# STM32F207 register map
File version: 1.2
CPU: CM3 r1p1, little endian, no MPU, no FPU, 4 interrupt priority bits
Registers are 32-bit, read-write, reset 0x0 unless marked. A register's access mark holds for its fields unless they carry their own. Offsets are from the block's base; [hi:lo] are bit positions; {n}, {i} and the like mark numbered series; 'fields as' and 'values as' point back to an identical list.

## Ethernet_PTP — Ethernet: Precision time protocol
Base 0x40028700
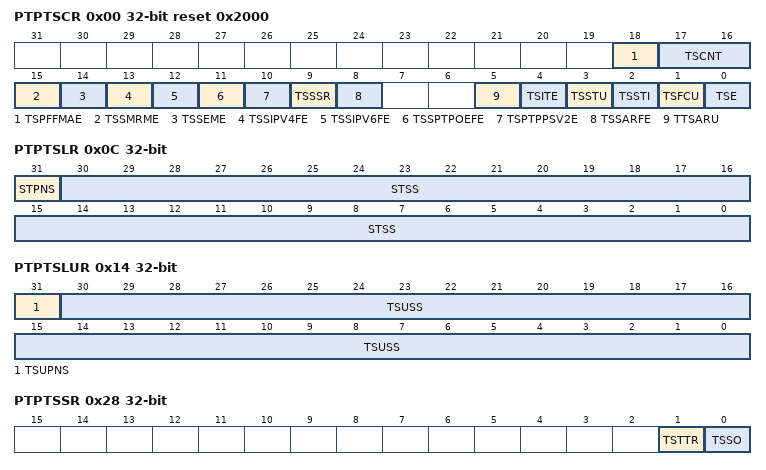
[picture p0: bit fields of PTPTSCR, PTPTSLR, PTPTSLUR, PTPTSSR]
0x00 PTPTSCR reset 0x2000 — Ethernet PTP time stamp control register
  [18] TSPFFMAE — Time stamp PTP frame filtering MAC address enable
  [17:16] TSCNT — Time stamp clock node type
  [15] TSSMRME — Time stamp snapshot for message relevant to master enable
  [14] TSSEME — Time stamp snapshot for event message enable
  [13] TSSIPV4FE — Time stamp snapshot for IPv4 frames enable
  [12] TSSIPV6FE — Time stamp snapshot for IPv6 frames enable
  [11] TSSPTPOEFE — Time stamp snapshot for PTP over ethernet frames enable
  [10] TSPTPPSV2E — Time stamp PTP packet snooping for version2 format enable
  [9] TSSSR — Time stamp subsecond rollover: digital or binary rollover control
  [8] TSSARFE — Time stamp snapshot for all received frames enable
  [5] TTSARU — Time stamp addend register update
  [4] TSITE — Time stamp interrupt trigger enable
  [3] TSSTU — Time stamp system time update
  [2] TSSTI — Time stamp system time initialize
  [1] TSFCU — Time stamp fine or coarse update
  [0] TSE — Time stamp enable
0x04 PTPSSIR — Ethernet PTP subsecond increment register
  [7:0] STSSI — System time subsecond increment
0x08 PTPTSHR ro — Ethernet PTP time stamp high register
  [31:0] STS — System time second
0x0C PTPTSLR ro — Ethernet PTP time stamp low register
  [31] STPNS — System time positive or negative sign
  [30:0] STSS — System time subseconds
0x10 PTPTSHUR — Ethernet PTP time stamp high update register
  [31:0] TSUS — Time stamp update second
0x14 PTPTSLUR — Ethernet PTP time stamp low update register
  [31] TSUPNS — Time stamp update positive or negative sign
  [30:0] TSUSS — Time stamp update subseconds
0x18 PTPTSAR — Ethernet PTP time stamp addend register
  [31:0] TSA — Time stamp addend
0x1C PTPTTHR — Ethernet PTP target time high register
  [31:0] TTSH — Target time stamp high
0x20 PTPTTLR — Ethernet PTP target time low register
  [31:0] TTSL — Target time stamp low
0x28 PTPTSSR ro — Ethernet PTP time stamp status register
  [1] TSTTR — Time stamp target time reached
  [0] TSSO — Time stamp second overflow
0x2C PTPPPSCR ro — Ethernet PTP PPS control register
  [3:0] PPSFREQ — PPS frequency selection

## FLASH
Base 0x40023C00
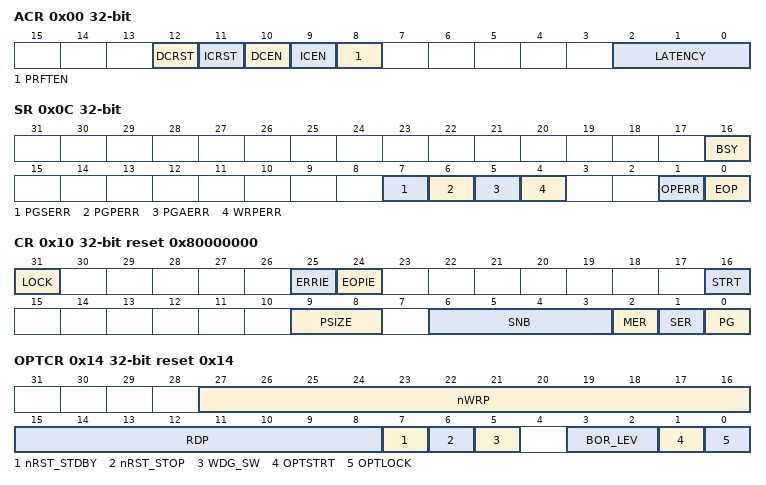
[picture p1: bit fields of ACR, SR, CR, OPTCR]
0x00 ACR access per field — Flash access control register
  [12] DCRST rw — Data cache reset
  [11] ICRST wo — Instruction cache reset
  [10] DCEN rw — Data cache enable
  [9] ICEN rw — Instruction cache enable
  [8] PRFTEN rw — Prefetch enable
  [2:0] LATENCY rw
0x04 KEYR wo — Flash key register
  [31:0] KEY — FPEC key
0x08 OPTKEYR wo — Flash option key register
  [31:0] OPTKEY — Option byte key
0x0C SR access per field — Status register
  [16] BSY ro — Busy
  [7] PGSERR rw — Programming sequence error
  [6] PGPERR rw — Programming parallelism error
  [5] PGAERR rw — Programming alignment error
  [4] WRPERR rw — Write protection error
  [1] OPERR rw — Operation error
  [0] EOP rw — End of operation
0x10 CR reset 0x80000000 — Control register
  [31] LOCK
  [25] ERRIE — Error interrupt enable
  [24] EOPIE — End of operation interrupt enable
  [16] STRT — Start
  [9:8] PSIZE — Program size
  [6:3] SNB — Sector number
  [2] MER — Mass Erase
  [1] SER — Sector Erase
  [0] PG — Programming
0x14 OPTCR reset 0x14 — Flash option control register
  [27:16] nWRP — Not write protect
  [15:8] RDP — Read protect
  [7] nRST_STDBY — nRST_STDBY User option bytes
  [6] nRST_STOP — nRST_STOP User option bytes
  [5] WDG_SW — WDG_SW User option bytes
  [3:2] BOR_LEV — BOR reset Level
  [1] OPTSTRT — Option start
  [0] OPTLOCK — Option lock

## FSMC — Flexible static memory controller
Base 0xA0000000
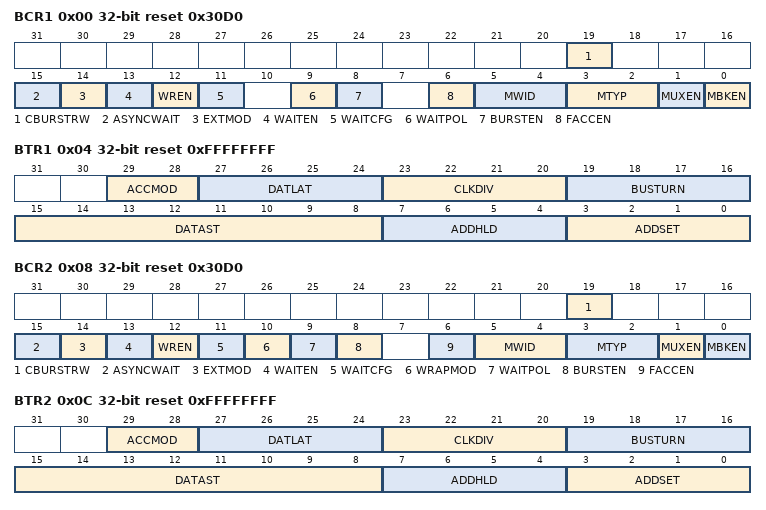
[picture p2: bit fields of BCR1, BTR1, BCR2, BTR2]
0x00 BCR1 reset 0x30D0 — SRAM/NOR-Flash chip-select control register 1
  [19] CBURSTRW, [15] ASYNCWAIT, [14] EXTMOD, [13] WAITEN, [12] WREN, [11] WAITCFG, [9] WAITPOL, [8] BURSTEN, [6] FACCEN, [5:4] MWID, [3:2] MTYP, [1] MUXEN, [0] MBKEN
0x04 BTR1 reset 0xFFFFFFFF — SRAM/NOR-Flash chip-select timing register 1
  [29:28] ACCMOD, [27:24] DATLAT, [23:20] CLKDIV, [19:16] BUSTURN, [15:8] DATAST, [7:4] ADDHLD, [3:0] ADDSET
0x08 BCR2 reset 0x30D0 — SRAM/NOR-Flash chip-select control register 2
  [19] CBURSTRW, [15] ASYNCWAIT, [14] EXTMOD, [13] WAITEN, [12] WREN, [11] WAITCFG, [10] WRAPMOD, [9] WAITPOL, [8] BURSTEN, [6] FACCEN, [5:4] MWID, [3:2] MTYP, [1] MUXEN, [0] MBKEN
0x0C BTR2 reset 0xFFFFFFFF — SRAM/NOR-Flash chip-select timing register 2
  fields as BTR1
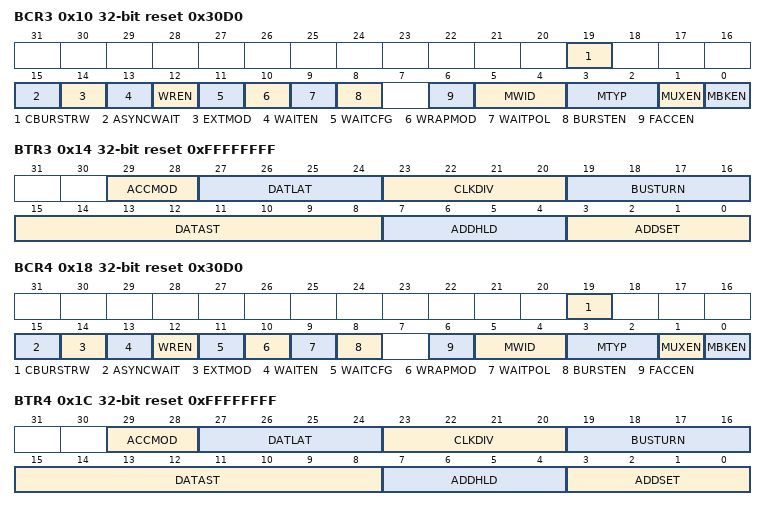
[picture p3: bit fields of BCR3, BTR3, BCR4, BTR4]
0x10 BCR3 reset 0x30D0 — SRAM/NOR-Flash chip-select control register 3
  fields as BCR2
0x14 BTR3 reset 0xFFFFFFFF — SRAM/NOR-Flash chip-select timing register 3
  fields as BTR1
0x18 BCR4 reset 0x30D0 — SRAM/NOR-Flash chip-select control register 4
  fields as BCR2
0x1C BTR4 reset 0xFFFFFFFF — SRAM/NOR-Flash chip-select timing register 4
  fields as BTR1
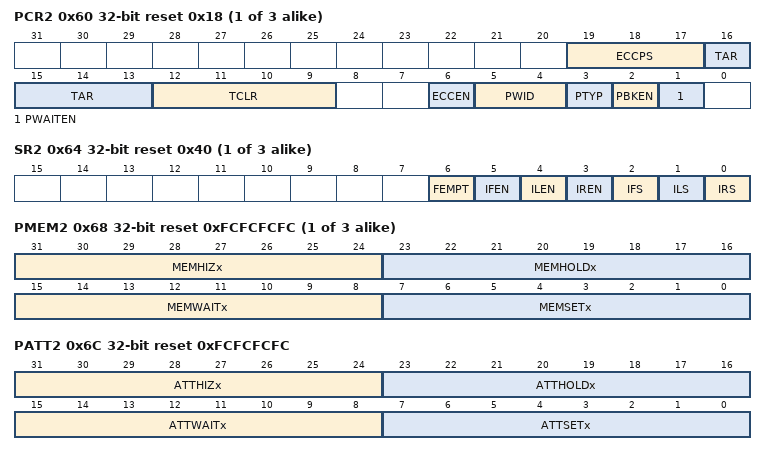
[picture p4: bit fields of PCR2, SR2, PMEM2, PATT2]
{0x20+0x20*i} PCR{i} reset 0x18 (i=2..4) — PC Card/NAND Flash control register {i}
  [19:17] ECCPS, [16:13] TAR, [12:9] TCLR, [6] ECCEN, [5:4] PWID, [3] PTYP, [2] PBKEN, [1] PWAITEN
{0x24+0x20*i} SR{i} access per field reset 0x40 (i=2..4) — FIFO status and interrupt register {i}
  [6] FEMPT ro, [5] IFEN rw, [4] ILEN rw, [3] IREN rw, [2] IFS rw, [1] ILS rw, [0] IRS rw
{0x28+0x20*i} PMEM{i} reset 0xFCFCFCFC (i=2..4) — Common memory space timing register {i}
  [31:24] MEMHIZx, [23:16] MEMHOLDx, [15:8] MEMWAITx, [7:0] MEMSETx
0x6C PATT2 reset 0xFCFCFCFC — Attribute memory space timing register 2
  [31:24] ATTHIZx — Attribute memory x databus HiZ time
  [23:16] ATTHOLDx — Attribute memory x hold time
  [15:8] ATTWAITx — Attribute memory x wait time
  [7:0] ATTSETx — Attribute memory x setup time
0x74 ECCR2 ro — ECC result register 2
  [31:0] ECCx — ECC result
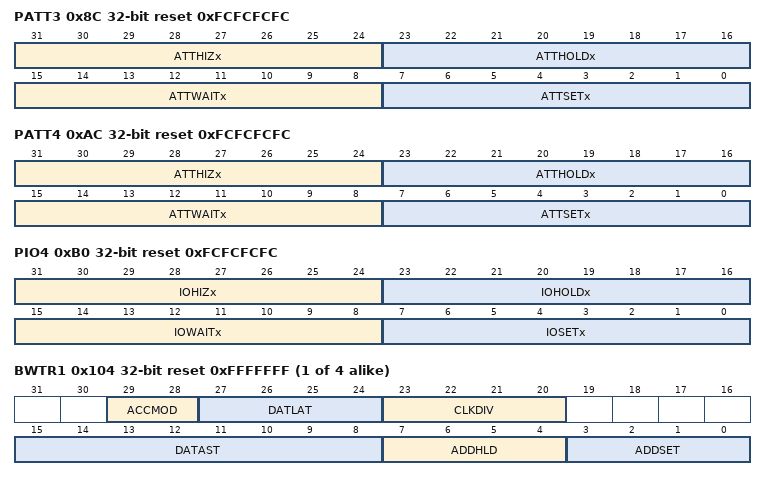
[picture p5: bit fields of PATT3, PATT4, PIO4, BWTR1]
0x8C PATT3 reset 0xFCFCFCFC — Attribute memory space timing register 3
  [31:24] ATTHIZx, [23:16] ATTHOLDx, [15:8] ATTWAITx, [7:0] ATTSETx
0x94 ECCR3 ro — ECC result register 3
  [31:0] ECCx
0xAC PATT4 reset 0xFCFCFCFC — Attribute memory space timing register 4
  [31:24] ATTHIZx, [23:16] ATTHOLDx, [15:8] ATTWAITx, [7:0] ATTSETx
0xB0 PIO4 reset 0xFCFCFCFC — I/O space timing register 4
  [31:24] IOHIZx, [23:16] IOHOLDx, [15:8] IOWAITx, [7:0] IOSETx
{0xFC+8i} BWTR{i} reset 0xFFFFFFF (i=1..4) — SRAM/NOR-Flash write timing registers {i}
  [29:28] ACCMOD, [27:24] DATLAT, [23:20] CLKDIV, [15:8] DATAST, [7:4] ADDHLD, [3:0] ADDSET
